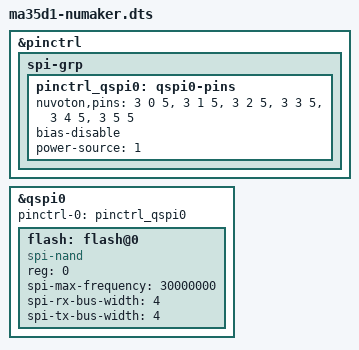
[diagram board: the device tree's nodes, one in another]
// SPDX-License-Identifier: GPL-2.0-only OR MIT
/*
 * Copyright (C) 2025 Bootlin
 * Author: Miquel Raynal <miquel.raynal@bootlin.com>
 */

/dts-v1/;
#include "ma35d1-som-256m.dts"

&pinctrl {
	spi-grp {
		pinctrl_qspi0: qspi0-pins {
			nuvoton,pins = <3 0 5>,
				       <3 1 5>,
				       <3 2 5>,
				       <3 3 5>,
				       <3 4 5>,
				       <3 5 5>;
			bias-disable;
			power-source = <1>;
		};
	};
};

&qspi0 {
	pinctrl-names = "default";
	pinctrl-0 = <&pinctrl_qspi0>;
	status = "okay";

	flash: flash@0 {
		compatible = "spi-nand";
		reg = <0>;
		spi-max-frequency = <30000000>;
		spi-rx-bus-width = <4>;
		spi-tx-bus-width = <4>;
	};
};
